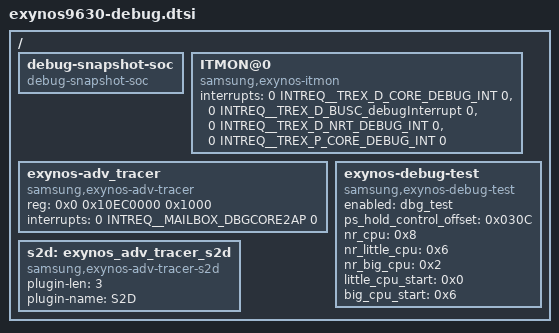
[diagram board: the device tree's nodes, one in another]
/*
 * SAMSUNG EXYNOS9630 SoC device tree source
 *
 * Copyright (c) 2019 Samsung Electronics Co., Ltd.
 *		http://www.samsung.com
 *
 * SAMSUNG EXYNOS9630 SoC device nodes are listed in this file.
 * EXYNOS9630 based board files can include this file and provide
 * values for board specfic bindings.
 *
 * This program is free software; you can redistribute it and/or modify
 * it under the terms of the GNU General Public License version 2 as
 * published by the Free Software Foundation.
 */

#include <dt-bindings/interrupt-controller/exynos9630.h>

/ {
	debug-snapshot-soc {
		compatible = "debug-snapshot-soc";
		#address-cells = <1>;
		#size-cells = <1>;
	};

	ITMON@0 {
		compatible = "samsung,exynos-itmon";
		interrupts = <0 INTREQ__TREX_D_CORE_DEBUG_INT 0>,
			     <0 INTREQ__TREX_D_BUSC_debugInterrupt 0>,
			     <0 INTREQ__TREX_D_NRT_DEBUG_INT 0>,
			     <0 INTREQ__TREX_P_CORE_DEBUG_INT 0>;
	};

        exynos-adv_tracer {
                compatible = "samsung,exynos-adv-tracer";
                reg = <0x0 0x10EC0000 0x1000>;
                reg-names = "mailbox";
                interrupts = <0 INTREQ__MAILBOX_DBGCORE2AP 0>;
                status = "ok";
	};

	s2d: exynos_adv_tracer_s2d {
		compatible = "samsung,exynos-adv-tracer-s2d";
		plugin-len = <3>;
		plugin-name = "S2D";
		status = "ok";
	};

	exynos-debug-test {
		compatible = "samsung,exynos-debug-test";
		enabled = "dbg_test";
		ps_hold_control_offset = <0x030C>;
		nr_cpu = <0x8>;
		nr_little_cpu = <0x6>;
		nr_big_cpu = <0x2>;
		little_cpu_start = <0x0>;
		big_cpu_start = <0x6>;
	};
};
